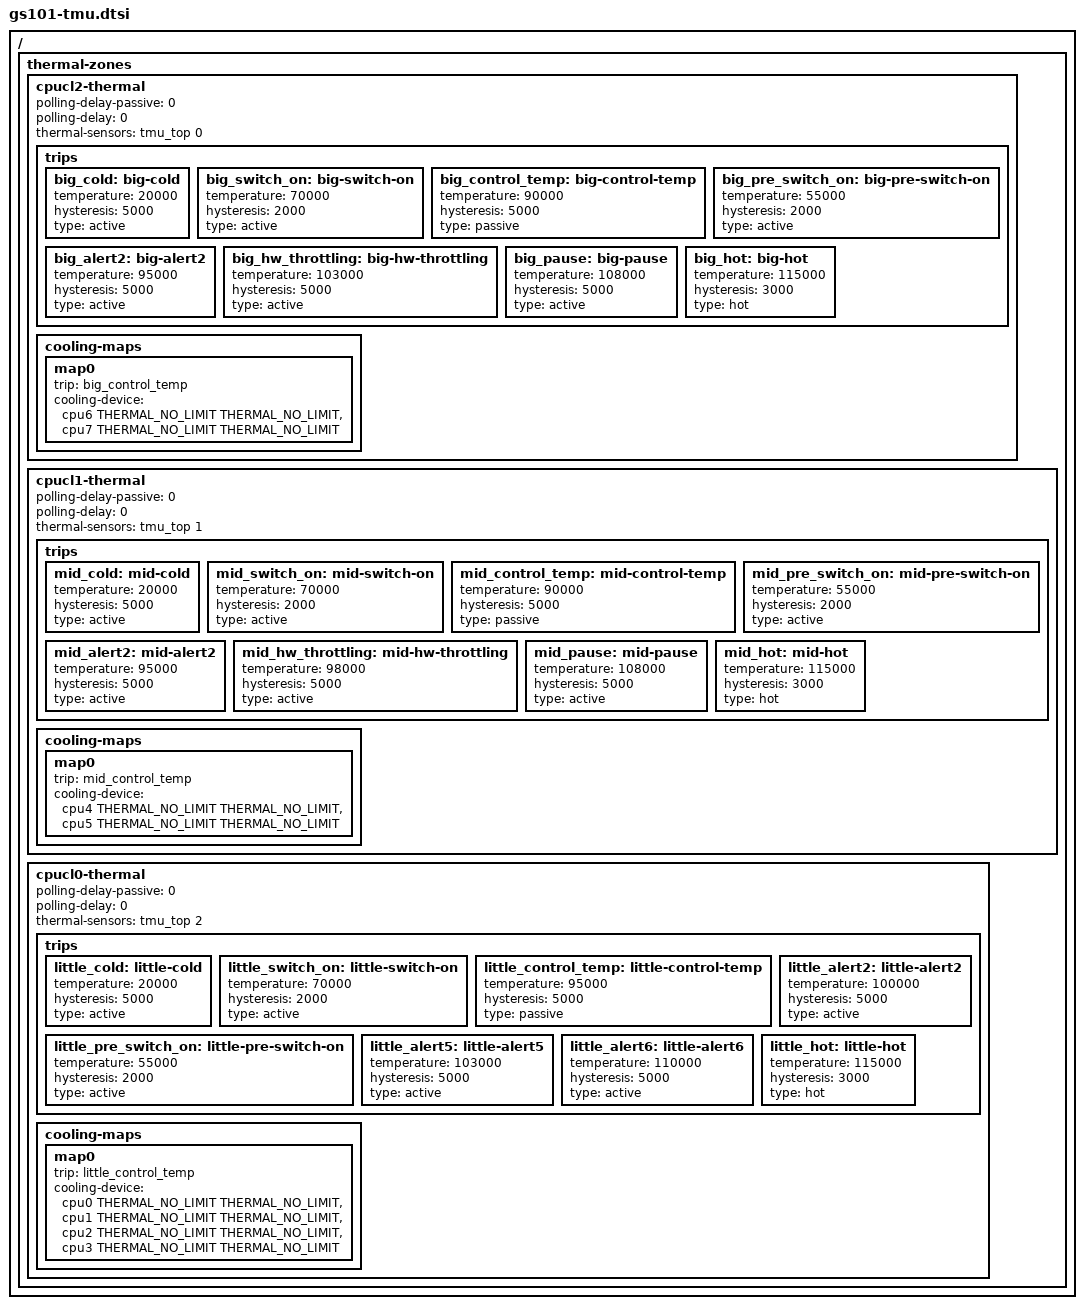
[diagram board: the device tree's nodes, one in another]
// SPDX-License-Identifier: GPL-2.0
/*
 * Google GS101 TMU configurations device tree source
 *
 * Copyright 2020 Samsung Electronics Co., Ltd.
 * Copyright 2020 Google LLC.
 * Copyright 2026 Linaro Ltd.
 */

#include <dt-bindings/thermal/thermal.h>

/ {
	thermal-zones {
		cpucl2-thermal {
			polling-delay-passive = <0>;
			polling-delay = <0>;
			thermal-sensors = <&tmu_top 0>;

			trips {
				big_cold: big-cold {
					temperature = <20000>;
					hysteresis = <5000>;
					type = "active";
				};

				big_switch_on: big-switch-on {
					temperature = <70000>;
					hysteresis = <2000>;
					type = "active";
				};

				big_control_temp: big-control-temp {
					temperature = <90000>;
					hysteresis = <5000>;
					type = "passive";
				};

				big_pre_switch_on: big-pre-switch-on {
					temperature = <55000>;
					hysteresis = <2000>;
					type = "active";
				};

				big_alert2: big-alert2 {
					temperature = <95000>;
					hysteresis = <5000>;
					type = "active";
				};

				big_hw_throttling: big-hw-throttling {
					temperature = <103000>;
					hysteresis = <5000>;
					type = "active";
				};

				big_pause: big-pause {
					temperature = <108000>;
					hysteresis = <5000>;
					type = "active";
				};

				big_hot: big-hot {
					temperature = <115000>;
					hysteresis = <3000>;
					type = "hot";
				};
			};

			cooling-maps {
				map0 {
					trip = <&big_control_temp>;
					cooling-device = <&cpu6 THERMAL_NO_LIMIT THERMAL_NO_LIMIT>,
							 <&cpu7 THERMAL_NO_LIMIT THERMAL_NO_LIMIT>;
				};
			};
		};

		cpucl1-thermal {
			polling-delay-passive = <0>;
			polling-delay = <0>;
			thermal-sensors = <&tmu_top 1>;

			trips {
				mid_cold: mid-cold {
					temperature = <20000>;
					hysteresis = <5000>;
					type = "active";
				};

				mid_switch_on: mid-switch-on {
					temperature = <70000>;
					hysteresis = <2000>;
					type = "active";
				};

				mid_control_temp: mid-control-temp {
					temperature = <90000>;
					hysteresis = <5000>;
					type = "passive";
				};

				mid_pre_switch_on: mid-pre-switch-on {
					temperature = <55000>;
					hysteresis = <2000>;
					type = "active";
				};

				mid_alert2: mid-alert2 {
					temperature = <95000>;
					hysteresis = <5000>;
					type = "active";
				};

				mid_hw_throttling: mid-hw-throttling {
					temperature = <98000>;
					hysteresis = <5000>;
					type = "active";
				};

				mid_pause: mid-pause {
					temperature = <108000>;
					hysteresis = <5000>;
					type = "active";
				};

				mid_hot: mid-hot {
					temperature = <115000>;
					hysteresis = <3000>;
					type = "hot";
				};
			};

			cooling-maps {
				map0 {
				     trip = <&mid_control_temp>;
					cooling-device = <&cpu4 THERMAL_NO_LIMIT THERMAL_NO_LIMIT>,
							 <&cpu5 THERMAL_NO_LIMIT THERMAL_NO_LIMIT>;
			       };
			};
		};

		cpucl0-thermal {
			polling-delay-passive = <0>;
			polling-delay = <0>;
			thermal-sensors = <&tmu_top 2>;

			trips {
				little_cold: little-cold {
					temperature = <20000>;
					hysteresis = <5000>;
					type = "active";
				};

				little_switch_on: little-switch-on {
					temperature = <70000>;
					hysteresis = <2000>;
					type = "active";
				};

				little_control_temp: little-control-temp {
					temperature = <95000>;
					hysteresis = <5000>;
					type = "passive";
				};

				little_pre_switch_on: little-pre-switch-on {
					temperature = <55000>;
					hysteresis = <2000>;
					type = "active";
				};

				little_alert2: little-alert2 {
					temperature = <100000>;
					hysteresis = <5000>;
					type = "active";
				};

				little_alert5: little-alert5 {
					temperature = <103000>;
					hysteresis = <5000>;
					type = "active";
				};

				little_alert6: little-alert6 {
					temperature = <110000>;
					hysteresis = <5000>;
					type = "active";
				};

				little_hot: little-hot {
					temperature = <115000>;
					hysteresis = <3000>;
					type = "hot";
				};
			};

			cooling-maps {
				map0 {
					trip = <&little_control_temp>;
					cooling-device = <&cpu0 THERMAL_NO_LIMIT THERMAL_NO_LIMIT>,
							 <&cpu1 THERMAL_NO_LIMIT THERMAL_NO_LIMIT>,
							 <&cpu2 THERMAL_NO_LIMIT THERMAL_NO_LIMIT>,
							 <&cpu3 THERMAL_NO_LIMIT THERMAL_NO_LIMIT>;
				};
			};
		};

	};
};
